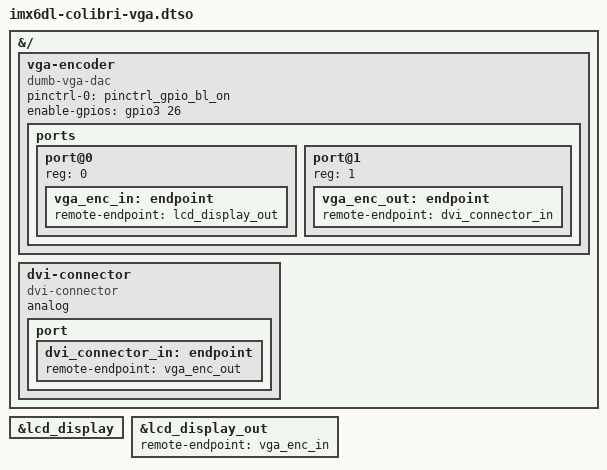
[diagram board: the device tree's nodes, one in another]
// SPDX-License-Identifier: GPL-2.0-only OR MIT
/*
 * Copyright (c) Toradex
 *
 * VGA output connected to the Colibri parallel RGB LCD interface through a
 * non-programmable video DAC with a DVI connector.
 *
 * The VGA output is available on multiple carrier boards (including Iris,
 * Eval, Aster) without VESA DDC I2C signals.
 *
 * The DAC power-save input is driven by the BL_ON signal on SODIMM 71.
 */

/dts-v1/;
/plugin/;

#include <dt-bindings/gpio/gpio.h>

&{/} {
	vga-encoder {
		compatible = "dumb-vga-dac";
		pinctrl-names = "default";
		pinctrl-0 = <&pinctrl_gpio_bl_on>;
		/* Colibri SODIMM 71 - BL_ON */
		enable-gpios = <&gpio3 26 GPIO_ACTIVE_HIGH>;

		ports {
			#address-cells = <1>;
			#size-cells = <0>;

			port@0 {
				reg = <0>;

				vga_enc_in: endpoint {
					remote-endpoint = <&lcd_display_out>;
				};
			};

			port@1 {
				reg = <1>;

				vga_enc_out: endpoint {
					remote-endpoint = <&dvi_connector_in>;
				};
			};
		};
	};

	dvi-connector {
		compatible = "dvi-connector";
		analog;

		port {
			dvi_connector_in: endpoint {
				remote-endpoint = <&vga_enc_out>;
			};
		};
	};
};

&lcd_display {
	status = "okay";
};

&lcd_display_out {
	remote-endpoint = <&vga_enc_in>;
};
